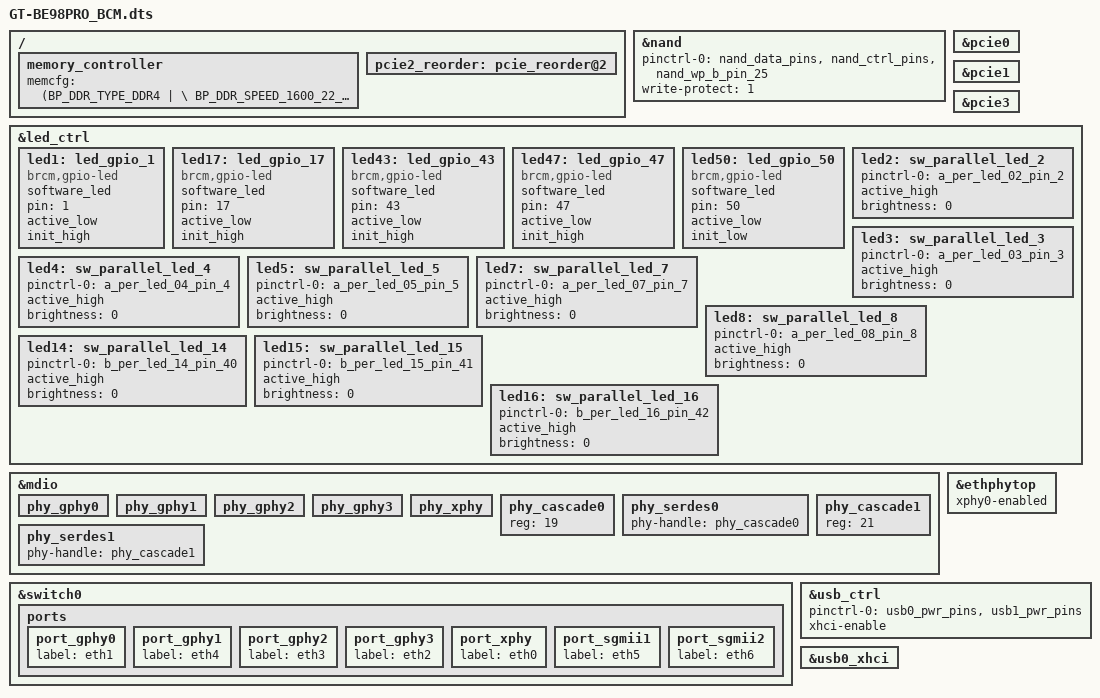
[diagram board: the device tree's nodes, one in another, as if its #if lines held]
#include "6813.dtsi"

#if defined(CONFIG_BCM_PCIE_HCD) || defined(CONFIG_BCM_PCIE_HCD_MODULE)
/delete-node/ &pcie2;
#endif //#if defined(CONFIG_BCM_PCIE_HCD) || defined(CONFIG_BCM_PCIE_HCD_MODULE)

/ {
	memory_controller {
		memcfg = <(BP_DDR_TYPE_DDR4       | \
			BP_DDR_SPEED_1600_22_22_22    | \
			BP_DDR_TOTAL_SIZE_2048MB      | \
			BP_DDR_DEVICE_WIDTH_16        | \
			BP_DDR_TOTAL_WIDTH_32BIT      | \
			BP_DDR_TEMP_EXTENDED_ASR      | \
			BP_DDR_SSC_CONFIG_1)>;
	};

#if defined(CONFIG_BCM_PCIE_HCD) || defined(CONFIG_BCM_PCIE_HCD_MODULE)
    /* pcie core 2 */
    pcie2_reorder: pcie_reorder@2 {                                                                                                                                                                                     
	#define PCIE_ID                         2
	#define PCIE_SPI                        70
	#define PCIE_ADDR                       0x800A0000
	#define PCIE_SIZE                       0x0000B000
	#define PCIE_RANGE_ADDR         0xE0000000
	#define PCIE_RANGE_SIZE         0x10000000
	#include "../ip/bcm_pcie_core.dtsi"
    };
#endif //#if defined(CONFIG_BCM_PCIE_HCD) || defined(CONFIG_BCM_PCIE_HCD_MODULE)

};

&nand {
	pinctrl-0 = <&nand_data_pins &nand_ctrl_pins &nand_wp_b_pin_25>;
	write-protect = <1>;
	status = "okay";
};

#if defined(CONFIG_BCM_PCIE_HCD) || defined(CONFIG_BCM_PCIE_HCD_MODULE)
&pcie0 {
	status = "okay";
};
&pcie1 {
	status = "okay";
};
&pcie2_reorder {
	status = "okay";
};
&pcie3 {
	status = "okay";
};
#endif //#if defined(CONFIG_BCM_PCIE_HCD) || defined(CONFIG_BCM_PCIE_HCD_MODULE)
/*
&legacy_leds {
    wl-sess-led = <&led27>;
};
*/
&led_ctrl {
	status="okay";

	/* GPIO LED */
	/* LAN LED */
	led1:led_gpio_1 {
		compatible = "brcm,gpio-led";
		software_led;
		pin = <1>;
		active_low;
		init_high;
	};
	/* WAN WHITE LED */
	led17:led_gpio_17 {
		compatible = "brcm,gpio-led";
		software_led;
		pin = <17>;
		active_low;
		init_high;
	};
	/* WAN RED LED */
	led43:led_gpio_43 {
		compatible = "brcm,gpio-led";
		software_led;
		pin = <43>;
		active_low;
		init_high;
	};
	/* 10G LAN LED */
	led47:led_gpio_47 {
		compatible = "brcm,gpio-led";
		software_led;
		pin = <47>;
		active_low;
		init_high;
	};
	/* POWER LED */
	led50:led_gpio_50 {
		compatible = "brcm,gpio-led";
		software_led;
		pin = <50>;
		active_low;
		init_low;
	};

	/* CLED */
	/* LED_1A_R */
	led2: sw_parallel_led_2 {
		pinctrl-0 = <&a_per_led_02_pin_2>;
		active_high;
		status="okay";
		brightness = <0>;
	};
	/* LED_1A_B */
	led3: sw_parallel_led_3 {
		pinctrl-0 = <&a_per_led_03_pin_3>;
		active_high;
		status="okay";
		brightness = <0>;
	};
	/* LED_1A_G */
	led4: sw_parallel_led_4 {
		pinctrl-0 = <&a_per_led_04_pin_4>;
		active_high;
		status="okay";
		brightness = <0>;
	};

	/* LED_1B_R */
	led5: sw_parallel_led_5 {
		pinctrl-0 = <&a_per_led_05_pin_5>;
		active_high;
		status="okay";
		brightness = <0>;
	};
	/* LED_1B_B */
	led7: sw_parallel_led_7 {
		pinctrl-0 = <&a_per_led_07_pin_7>;
		active_high;
		status="okay";
		brightness = <0>;
	};
	/* LED_1B_G */
	led8: sw_parallel_led_8 {
		pinctrl-0 = <&a_per_led_08_pin_8>;
		active_high;
		status="okay";
		brightness = <0>;
	};
	/* LED_1C_R */
	led14: sw_parallel_led_14 {
		pinctrl-0 = <&b_per_led_14_pin_40>;
		active_high;
		status="okay";
		brightness = <0>;
	};
	/* LED_1C_B */
	led15: sw_parallel_led_15 {
		pinctrl-0 = <&b_per_led_15_pin_41>;
		active_high;
		status="okay";
		brightness = <0>;
	};
	/* LED_1C_G */
	led16: sw_parallel_led_16 {
		pinctrl-0 = <&b_per_led_16_pin_42>;
		active_high;
		status="okay";
		brightness = <0>;
	};
};

/* For AURA72UB0, NP for now
&i2c1 {
	pinctrl-names = "default";
	pinctrl-0 = <&i2c1_sclk_pin_14 &i2c1_sdata_pin_15>;
	status = "okay";
};
*/

&mdio {
    /* Port PHY mapping:
        port_gphy0 <----> phy_gphy0
        port_gphy1 <----> phy_gphy1
        port_gphy2 <----> phy_gphy2
        port_gphy3 <----> phy_gphy3
        port_xphy <-----> phy_xphy      - Internal 10G PHY
        port_sgmii1 <---> phy_serdes0   - BCM84891L
        port_sgmii2 <---> phy_serdes1   - BCM84891L
     */
	phy_gphy0 {
		status = "okay";
	};

	phy_gphy1 {
		status = "okay";
	};

	phy_gphy2 {
		status = "okay";
	};

	phy_gphy3 {
		status = "okay";
	};

	phy_xphy {
		status = "okay";
	};

        phy_cascade0 {
        reg = <19>;
		status = "okay";
	};

	phy_serdes0 {
		phy-handle = <&phy_cascade0>;
		status = "okay";
	};

        phy_cascade1 {
        reg = <21>;
		status = "okay";
	};

	phy_serdes1 {
		phy-handle = <&phy_cascade1>;
		status = "okay";
	};
};

&ethphytop {
    xphy0-enabled;
    status = "okay";
};

&switch0 {
	ports {
		port_gphy0 {
			status = "okay";
			label = "eth1";
		};

		port_gphy1 {
			status = "okay";
			label = "eth4";
		};

		port_gphy2 {
			status = "okay";
			label = "eth3";
		};

		port_gphy3 {
			status = "okay";
			label = "eth2";
		};

		port_xphy {
			status = "okay";
			label = "eth0";
		};

		port_sgmii1 {
			status = "okay";
			label = "eth5";
		};

		port_sgmii2 {
			status = "okay";
			label = "eth6";
		};
	};
};

&usb_ctrl {
	pinctrl-names = "default";
	pinctrl-0 = <&usb0_pwr_pins &usb1_pwr_pins>;
	status = "okay";
	xhci-enable;
};
&usb0_xhci {
	status = "okay";
};
